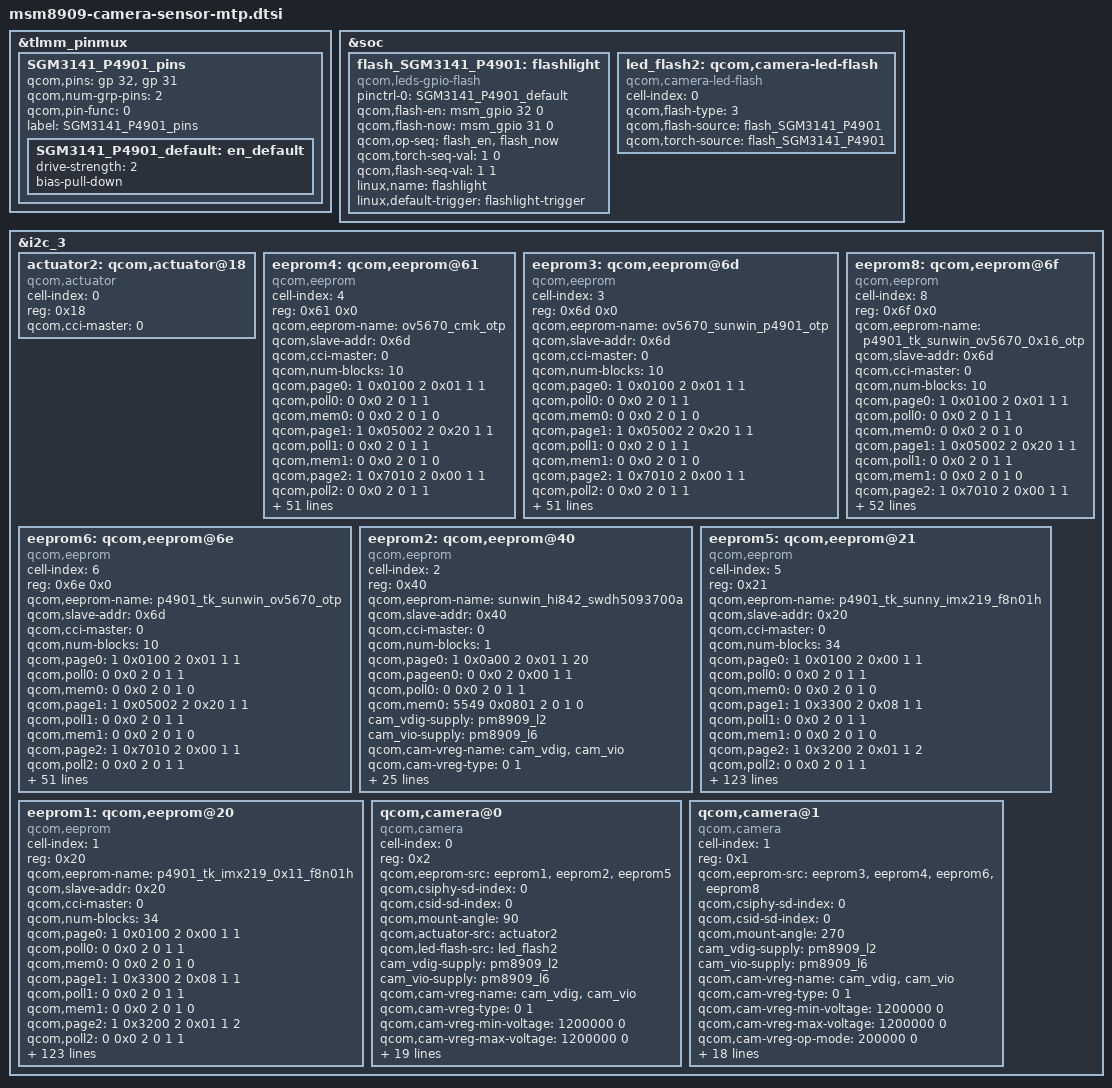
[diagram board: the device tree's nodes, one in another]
/*
 * Copyright (c) 2014-2015, The Linux Foundation. All rights reserved.
 *
 * This program is free software; you can redistribute it and/or modify
 * it under the terms of the GNU General Public License version 2 and
 * only version 2 as published by the Free Software Foundation.
 *
 * This program is distributed in the hope that it will be useful,
 * but WITHOUT ANY WARRANTY; without even the implied warranty of
 * MERCHANTABILITY or FITNESS FOR A PARTICULAR PURPOSE.  See the
 * GNU General Public License for more details.
 */

&tlmm_pinmux {
	SGM3141_P4901_pins {
		qcom,pins = <&gp 32>, <&gp 31>;
		qcom,num-grp-pins = <2>;
		qcom,pin-func = <0>;
		label = "SGM3141_P4901_pins";
		SGM3141_P4901_default: en_default {
		drive-strength = <2>;
		bias-pull-down;
		};
	};
};

&soc {
	flash_SGM3141_P4901:flashlight {
		compatible = "qcom,leds-gpio-flash";
		status = "okay";
		pinctrl-names = "flash_default";
		pinctrl-0 = <&SGM3141_P4901_default>;
		qcom,flash-en = <&msm_gpio 32 0>;
		qcom,flash-now = <&msm_gpio 31 0>;
		qcom,op-seq = "flash_en", "flash_now";
		qcom,torch-seq-val = <1 0>;
		qcom,flash-seq-val = <1 1>;
		linux,name = "flashlight";
		linux,default-trigger = "flashlight-trigger";
	};
	led_flash2: qcom,camera-led-flash {
		cell-index = <0>;
		compatible = "qcom,camera-led-flash";
		qcom,flash-type = <3>;
		qcom,flash-source = <&flash_SGM3141_P4901>;
		qcom,torch-source = <&flash_SGM3141_P4901>;
	};
};

&i2c_3 {

	actuator2: qcom,actuator@18 {
		cell-index = <0>;
		reg = <0x18>;
		compatible = "qcom,actuator";
		qcom,cci-master = <0>;
	};

      //ov5670 cmk
      eeprom4: qcom,eeprom@61{
		cell-index = <4>;
		reg = <0x61 0x0>;
		qcom,eeprom-name = "ov5670_cmk_otp";
		compatible = "qcom,eeprom";
		qcom,slave-addr = <0x6d>;
		qcom,cci-master = <0>;
		qcom,num-blocks = <10>;

		qcom,page0 = <1 0x0100 2 0x01 1 1>;
		qcom,poll0 = <0 0x0 2 0 1 1>;
		qcom,mem0 = <0 0x0 2 0 1 0>;

		qcom,page1 = <1 0x05002 2 0x20 1 1>;
		qcom,poll1 = <0 0x0 2 0 1 1>;
		qcom,mem1 = <0 0x0 2 0 1 0>;

		qcom,page2 = <1 0x7010 2 0x00 1 1>;
		qcom,poll2 = <0 0x0 2 0 1 1>;
		qcom,mem2 = <0 0x0 2 0 1 0>;

		qcom,page3 = <1 0x3d84 2 0xc0 1 1>;
		qcom,poll3 = <0 0x0 2 0 1 1>;
		qcom,mem3 = <0 0x0 2 0 1 0>;

		qcom,page4 = <1 0x3d88 2 0x70 1 1>;
		qcom,poll4 = <0 0x0 2 0 1 1>;
		qcom,mem4 = <0 0x0 2 0 1 0>;

		qcom,page5 = <1 0x3d89 2 0x10 1 1>;
		qcom,poll5 = <0 0x0 2 0 1 1>;
		qcom,mem5 = <0 0x0 2 0 1 0>;

		qcom,page6 = <1 0x3d8a 2 0x70 1 1>;
		qcom,poll6 = <0 0x0 2 0 1 1>;
		qcom,mem6 = <0 0x0 2 0 1 0>;

		qcom,page7 = <1 0x3d8b 2 0x29 1 1>;
		qcom,poll7 = <0 0x0 2 0 1 1>;
		qcom,mem7 = <0 0x0 2 0 1 0>;

		qcom,page8 = <1 0x3d81 2 0x01 1 2>;
		qcom,poll8 = <0 0x0 2 0 1 1>;
		qcom,mem8 = <26 0x7010 2 0 1 1>;

		qcom,page9 = <1 0x05002 2 0x28 1 1>;
		qcom,poll9 = <0 0x0 2 0 1 1>;
		qcom,mem9 = <0 0x0 2 0 1 0>;

		cam_vdig-supply = <&pm8909_l2>;
		cam_vio-supply = <&pm8909_l6>;
		qcom,cam-vreg-name = "cam_vdig","cam_vio";
		qcom,cam-vreg-type = <0 1>;
		qcom,cam-vreg-min-voltage = <1200000 0>;
		qcom,cam-vreg-max-voltage = <1200000 0>;
		qcom,cam-vreg-op-mode = <200000 0>;
		pinctrl-names = "cam_default", "cam_suspend";
		pinctrl-0 = <&cam_sensor_mclk1_default
				&cam_sensor_front_default>;
		pinctrl-1 = <&cam_sensor_mclk1_sleep &cam_sensor_front_sleep>;
		gpios = <&msm_gpio 27 0>,
			<&msm_gpio 28 0>,
			<&msm_gpio 33 0>,
			<&msm_gpio 112 0>;
		qcom,gpio-reset = <1>;
		qcom,gpio-standby = <2>;
		qcom,gpio-vana = <3>;
		qcom,gpio-req-tbl-num = <0 1 2 3>;
		qcom,gpio-req-tbl-flags = <1 0 0 0>;
		qcom,gpio-req-tbl-label = "CAMIF_MCLK",
					"CAM_RESET",
					"CAM_STANDBY",
					"CAM_VANA";
		qcom,cam-power-seq-type = "sensor_clk",
			"sensor_gpio",
			"sensor_gpio",
			"sensor_gpio";
		qcom,cam-power-seq-val = "sensor_cam_mclk",
			"sensor_gpio_reset",
			"sensor_gpio_standby",
			"sensor_gpio_vana";
		qcom,cam-power-seq-cfg-val = <24000000 1 1 1>;
		qcom,cam-power-seq-delay = <5 10 10 10>;

		clocks = <&clock_gcc clk_mclk1_clk_src>,
				<&clock_gcc clk_gcc_camss_mclk1_clk>;
		clock-names = "cam_src_clk", "cam_clk";
	};

      //ov5670
      eeprom3: qcom,eeprom@6d{
		cell-index = <3>;
		reg = <0x6d 0x0>;
		qcom,eeprom-name = "ov5670_sunwin_p4901_otp";
		compatible = "qcom,eeprom";
		qcom,slave-addr = <0x6d>;
		qcom,cci-master = <0>;
		qcom,num-blocks = <10>;

		qcom,page0 = <1 0x0100 2 0x01 1 1>;
		qcom,poll0 = <0 0x0 2 0 1 1>;
		qcom,mem0 = <0 0x0 2 0 1 0>;

		qcom,page1 = <1 0x05002 2 0x20 1 1>;
		qcom,poll1 = <0 0x0 2 0 1 1>;
		qcom,mem1 = <0 0x0 2 0 1 0>;

		qcom,page2 = <1 0x7010 2 0x00 1 1>;
		qcom,poll2 = <0 0x0 2 0 1 1>;
		qcom,mem2 = <0 0x0 2 0 1 0>;

		qcom,page3 = <1 0x3d84 2 0xc0 1 1>;
		qcom,poll3 = <0 0x0 2 0 1 1>;
		qcom,mem3 = <0 0x0 2 0 1 0>;

		qcom,page4 = <1 0x3d88 2 0x70 1 1>;
		qcom,poll4 = <0 0x0 2 0 1 1>;
		qcom,mem4 = <0 0x0 2 0 1 0>;

		qcom,page5 = <1 0x3d89 2 0x10 1 1>;
		qcom,poll5 = <0 0x0 2 0 1 1>;
		qcom,mem5 = <0 0x0 2 0 1 0>;

		qcom,page6 = <1 0x3d8a 2 0x70 1 1>;
		qcom,poll6 = <0 0x0 2 0 1 1>;
		qcom,mem6 = <0 0x0 2 0 1 0>;

		qcom,page7 = <1 0x3d8b 2 0x29 1 1>;
		qcom,poll7 = <0 0x0 2 0 1 1>;
		qcom,mem7 = <0 0x0 2 0 1 0>;

		qcom,page8 = <1 0x3d81 2 0x01 1 2>;
		qcom,poll8 = <0 0x0 2 0 1 1>;
		qcom,mem8 = <26 0x7010 2 0 1 1>;

		qcom,page9 = <1 0x05002 2 0x28 1 1>;
		qcom,poll9 = <0 0x0 2 0 1 1>;
		qcom,mem9 = <0 0x0 2 0 1 0>;

		cam_vdig-supply = <&pm8909_l2>;
		cam_vio-supply = <&pm8909_l6>;
		qcom,cam-vreg-name = "cam_vdig","cam_vio";
		qcom,cam-vreg-type = <0 1>;
		qcom,cam-vreg-min-voltage = <1200000 0>;
		qcom,cam-vreg-max-voltage = <1200000 0>;
		qcom,cam-vreg-op-mode = <200000 0>;
		pinctrl-names = "cam_default", "cam_suspend";
		pinctrl-0 = <&cam_sensor_mclk1_default
				&cam_sensor_front_default>;
		pinctrl-1 = <&cam_sensor_mclk1_sleep &cam_sensor_front_sleep>;
		gpios = <&msm_gpio 27 0>,
			<&msm_gpio 28 0>,
			<&msm_gpio 33 0>,
			<&msm_gpio 112 0>;
		qcom,gpio-reset = <1>;
		qcom,gpio-standby = <2>;
		qcom,gpio-vana = <3>;
		qcom,gpio-req-tbl-num = <0 1 2 3>;
		qcom,gpio-req-tbl-flags = <1 0 0 0>;
		qcom,gpio-req-tbl-label = "CAMIF_MCLK",
					"CAM_RESET",
					"CAM_STANDBY",
					"CAM_VANA";
		qcom,cam-power-seq-type = "sensor_clk",
			"sensor_gpio",
			"sensor_gpio",
			"sensor_gpio";
		qcom,cam-power-seq-val = "sensor_cam_mclk",
			"sensor_gpio_reset",
			"sensor_gpio_standby",
			"sensor_gpio_vana";
		qcom,cam-power-seq-cfg-val = <24000000 1 1 1>;
		qcom,cam-power-seq-delay = <5 10 10 10>;

		clocks = <&clock_gcc clk_mclk1_clk_src>,
				<&clock_gcc clk_gcc_camss_mclk1_clk>;
		clock-names = "cam_src_clk", "cam_clk";
	};


 //ov5670 tk 0x16
      eeprom8: qcom,eeprom@6f{
		cell-index = <8>;
		reg = <0x6f 0x0>;
		qcom,eeprom-name = "p4901_tk_sunwin_ov5670_0x16_otp";
		compatible = "qcom,eeprom";
		qcom,slave-addr = <0x6d>;
		qcom,cci-master = <0>;
		qcom,num-blocks = <10>;

		qcom,page0 = <1 0x0100 2 0x01 1 1>;
		qcom,poll0 = <0 0x0 2 0 1 1>;
		qcom,mem0 = <0 0x0 2 0 1 0>;

		qcom,page1 = <1 0x05002 2 0x20 1 1>;
		qcom,poll1 = <0 0x0 2 0 1 1>;
		qcom,mem1 = <0 0x0 2 0 1 0>;

		qcom,page2 = <1 0x7010 2 0x00 1 1>;
		qcom,poll2 = <0 0x0 2 0 1 1>;
		qcom,mem2 = <0 0x0 2 0 1 0>;

		qcom,page3 = <1 0x3d84 2 0xc0 1 1>;
		qcom,poll3 = <0 0x0 2 0 1 1>;
		qcom,mem3 = <0 0x0 2 0 1 0>;

		qcom,page4 = <1 0x3d88 2 0x70 1 1>;
		qcom,poll4 = <0 0x0 2 0 1 1>;
		qcom,mem4 = <0 0x0 2 0 1 0>;

		qcom,page5 = <1 0x3d89 2 0x10 1 1>;
		qcom,poll5 = <0 0x0 2 0 1 1>;
		qcom,mem5 = <0 0x0 2 0 1 0>;

		qcom,page6 = <1 0x3d8a 2 0x70 1 1>;
		qcom,poll6 = <0 0x0 2 0 1 1>;
		qcom,mem6 = <0 0x0 2 0 1 0>;

		qcom,page7 = <1 0x3d8b 2 0x29 1 1>;
		qcom,poll7 = <0 0x0 2 0 1 1>;
		qcom,mem7 = <0 0x0 2 0 1 0>;

		qcom,page8 = <1 0x3d81 2 0x01 1 2>;
		qcom,poll8 = <0 0x0 2 0 1 1>;
		qcom,mem8 = <26 0x7010 2 0 1 1>;

		qcom,page9 = <1 0x05002 2 0x28 1 1>;
		qcom,poll9 = <0 0x0 2 0 1 1>;
		qcom,mem9 = <0 0x0 2 0 1 0>;

		cam_vdig-supply = <&pm8909_l2>;
		cam_vio-supply = <&pm8909_l6>;
		qcom,cam-vreg-name = "cam_vdig","cam_vio";
		qcom,cam-vreg-type = <0 1>;
		qcom,cam-vreg-min-voltage = <1200000 0>;
		qcom,cam-vreg-max-voltage = <1200000 0>;
		qcom,cam-vreg-op-mode = <200000 0>;
		pinctrl-names = "cam_default", "cam_suspend";
		pinctrl-0 = <&cam_sensor_mclk1_default
				&cam_sensor_front_default>;
		pinctrl-1 = <&cam_sensor_mclk1_sleep &cam_sensor_front_sleep>;
		gpios = <&msm_gpio 27 0>,
			<&msm_gpio 28 0>,
			<&msm_gpio 33 0>,
			<&msm_gpio 112 0>;
		qcom,gpio-reset = <1>;
		qcom,gpio-standby = <2>;
		qcom,gpio-vana = <3>;
		qcom,gpio-req-tbl-num = <0 1 2 3>;
		qcom,gpio-req-tbl-flags = <1 0 0 0>;
		qcom,gpio-req-tbl-label = "CAMIF_MCLK",
					"CAM_RESET",
					"CAM_STANDBY",
					"CAM_VANA";
		qcom,cam-power-seq-type = "sensor_clk",
			"sensor_gpio",
			"sensor_gpio",
			"sensor_gpio";
		qcom,cam-power-seq-val = "sensor_cam_mclk",
			"sensor_gpio_reset",
			"sensor_gpio_standby",
			"sensor_gpio_vana";
		qcom,cam-power-seq-cfg-val = <24000000 1 1 1>;
		qcom,cam-power-seq-delay = <5 10 10 10>;

		clocks = <&clock_gcc clk_mclk1_clk_src>,
				<&clock_gcc clk_gcc_camss_mclk1_clk>;
		clock-names = "cam_src_clk", "cam_clk";
	};

 //ov5670 tk
      eeprom6: qcom,eeprom@6e{
		cell-index = <6>;
		reg = <0x6e 0x0>;
		qcom,eeprom-name = "p4901_tk_sunwin_ov5670_otp";
		compatible = "qcom,eeprom";
		qcom,slave-addr = <0x6d>;
		qcom,cci-master = <0>;
		qcom,num-blocks = <10>;

		qcom,page0 = <1 0x0100 2 0x01 1 1>;
		qcom,poll0 = <0 0x0 2 0 1 1>;
		qcom,mem0 = <0 0x0 2 0 1 0>;

		qcom,page1 = <1 0x05002 2 0x20 1 1>;
		qcom,poll1 = <0 0x0 2 0 1 1>;
		qcom,mem1 = <0 0x0 2 0 1 0>;

		qcom,page2 = <1 0x7010 2 0x00 1 1>;
		qcom,poll2 = <0 0x0 2 0 1 1>;
		qcom,mem2 = <0 0x0 2 0 1 0>;

		qcom,page3 = <1 0x3d84 2 0xc0 1 1>;
		qcom,poll3 = <0 0x0 2 0 1 1>;
		qcom,mem3 = <0 0x0 2 0 1 0>;

		qcom,page4 = <1 0x3d88 2 0x70 1 1>;
		qcom,poll4 = <0 0x0 2 0 1 1>;
		qcom,mem4 = <0 0x0 2 0 1 0>;

		qcom,page5 = <1 0x3d89 2 0x10 1 1>;
		qcom,poll5 = <0 0x0 2 0 1 1>;
		qcom,mem5 = <0 0x0 2 0 1 0>;

		qcom,page6 = <1 0x3d8a 2 0x70 1 1>;
		qcom,poll6 = <0 0x0 2 0 1 1>;
		qcom,mem6 = <0 0x0 2 0 1 0>;

		qcom,page7 = <1 0x3d8b 2 0x29 1 1>;
		qcom,poll7 = <0 0x0 2 0 1 1>;
		qcom,mem7 = <0 0x0 2 0 1 0>;

		qcom,page8 = <1 0x3d81 2 0x01 1 2>;
		qcom,poll8 = <0 0x0 2 0 1 1>;
		qcom,mem8 = <26 0x7010 2 0 1 1>;

		qcom,page9 = <1 0x05002 2 0x28 1 1>;
		qcom,poll9 = <0 0x0 2 0 1 1>;
		qcom,mem9 = <0 0x0 2 0 1 0>;

		cam_vdig-supply = <&pm8909_l2>;
		cam_vio-supply = <&pm8909_l6>;
		qcom,cam-vreg-name = "cam_vdig","cam_vio";
		qcom,cam-vreg-type = <0 1>;
		qcom,cam-vreg-min-voltage = <1200000 0>;
		qcom,cam-vreg-max-voltage = <1200000 0>;
		qcom,cam-vreg-op-mode = <200000 0>;
		pinctrl-names = "cam_default", "cam_suspend";
		pinctrl-0 = <&cam_sensor_mclk1_default
				&cam_sensor_front_default>;
		pinctrl-1 = <&cam_sensor_mclk1_sleep &cam_sensor_front_sleep>;
		gpios = <&msm_gpio 27 0>,
			<&msm_gpio 28 0>,
			<&msm_gpio 33 0>,
			<&msm_gpio 112 0>;
		qcom,gpio-reset = <1>;
		qcom,gpio-standby = <2>;
		qcom,gpio-vana = <3>;
		qcom,gpio-req-tbl-num = <0 1 2 3>;
		qcom,gpio-req-tbl-flags = <1 0 0 0>;
		qcom,gpio-req-tbl-label = "CAMIF_MCLK",
					"CAM_RESET",
					"CAM_STANDBY",
					"CAM_VANA";
		qcom,cam-power-seq-type = "sensor_clk",
			"sensor_gpio",
			"sensor_gpio",
			"sensor_gpio";
		qcom,cam-power-seq-val = "sensor_cam_mclk",
			"sensor_gpio_reset",
			"sensor_gpio_standby",
			"sensor_gpio_vana";
		qcom,cam-power-seq-cfg-val = <24000000 1 1 1>;
		qcom,cam-power-seq-delay = <5 10 10 10>;

		clocks = <&clock_gcc clk_mclk1_clk_src>,
				<&clock_gcc clk_gcc_camss_mclk1_clk>;
		clock-names = "cam_src_clk", "cam_clk";
	};

        //HI842
	eeprom2: qcom,eeprom@40 {
		cell-index = <2>;
		reg = <0x40>;
		qcom,eeprom-name = "sunwin_hi842_swdh5093700a";
		compatible = "qcom,eeprom";
		qcom,slave-addr = <0x40>;
		qcom,cci-master = <0>;
		qcom,num-blocks = <1>;

		qcom,page0 = <1 0x0a00 2 0x01 1 20>;//sensor  sleep read regs
		qcom,pageen0 = <0 0x0 2 0x00 1 1>;
		qcom,poll0 = <0 0x0 2 0 1 1>;
		qcom,mem0 = <5549 0x0801 2 0 1 0>;

		cam_vdig-supply = <&pm8909_l2>;
		cam_vio-supply = <&pm8909_l6>;
		qcom,cam-vreg-name = "cam_vdig","cam_vio";
		qcom,cam-vreg-type = <0 1>;
		qcom,cam-vreg-min-voltage = <1200000 0>;
		qcom,cam-vreg-max-voltage = <1200000 0>;
		qcom,cam-vreg-op-mode = <200000 0>;
		pinctrl-names = "cam_default", "cam_suspend";
		pinctrl-0 = <&cam_sensor_mclk0_default &cam_sensor_rear_default>;
		pinctrl-1 = <&cam_sensor_mclk0_sleep &cam_sensor_rear_sleep>;
		gpios = <&msm_gpio 26 0>,
			<&msm_gpio 35 0>,
			<&msm_gpio 34 0>,
			<&msm_gpio 112 0>;
		qcom,gpio-reset = <1>;
		qcom,gpio-standby = <2>;
		qcom,gpio-vana = <3>;
		qcom,gpio-req-tbl-num = <0 1 2 3>;
		qcom,gpio-req-tbl-flags = <1 0 0 0>;
		qcom,gpio-req-tbl-label = "CAMIF_MCLK",
			"CAM_RESET1",
			"CAM_STANDBY",
			"CAM_VANA";
		qcom,cam-power-seq-type = "sensor_clk",
			"sensor_gpio",
			"sensor_gpio",
			"sensor_gpio";
		qcom,cam-power-seq-val = "sensor_cam_mclk",
			"sensor_gpio_reset",
			"sensor_gpio_standby",
			"sensor_gpio_vana";
		qcom,cam-power-seq-cfg-val = <24000000 1 1 1>;
		qcom,cam-power-seq-delay = <5 10 10 10>;

		clocks = <&clock_gcc clk_mclk0_clk_src>,
				<&clock_gcc clk_gcc_camss_mclk0_clk>;
		clock-names = "cam_src_clk", "cam_clk";
	};

        //IMX219 TK 4901
	eeprom5: qcom,eeprom@21{
		cell-index = <5>;
		reg = <0x21>;
		qcom,eeprom-name = "p4901_tk_sunny_imx219_f8n01h";
		compatible = "qcom,eeprom";
		qcom,slave-addr = <0x20>;
		qcom,cci-master = <0>;
		qcom,num-blocks = <34>;

		qcom,page0 = <1 0x0100 2 0x00 1 1>; //SW Standby
		qcom,poll0 = <0 0x0 2 0 1 1>;
		qcom,mem0 = <0 0x0 2 0 1 0>;
/************************module info and af info********************************/
		qcom,page1 = <1 0x3300 2 0x08 1 1>; //ECC OFF
		qcom,poll1 = <0 0x0 2 0 1 1>;
		qcom,mem1 = <0 0x0 2 0 1 0>;
		qcom,page2 = <1 0x3200 2 0x01 1 2>; //Read mode on
		qcom,poll2 = <0 0x0 2 0 1 1>;
		qcom,mem2 = <0 0x0 2 0 1 0>;
		qcom,page3 = <1 0x3202 2 0x00 1 5>; //Page 0
		qcom,poll3 = <0 0x0 2 0 1 1>;
		qcom,mem3 = <64 0x3204 2 0 1 0>;

/**********************************awb info*************************************/
		qcom,page4 = <1 0x3300 2 0x08 1 1>; //ECC OFF
		qcom,poll4 = <0 0x0 2 0 1 1>;
		qcom,mem4 = <0 0x0 2 0 1 0>;
		qcom,page5 = <1 0x3200 2 0x01 1 2>; //Read mode on
		qcom,poll5 = <0 0x0 2 0 1 1>;
		qcom,mem5 = <0 0x0 2 0 1 0>;
		qcom,page6 = <1 0x3202 2 0x01 1 5>; //Page 1
		qcom,poll6 = <0 0x0 2 0 1 1>;
		qcom,mem6 = <64 0x3204 2 0 1 0>;

/******************************lsc info group 1*********************************/
		qcom,page7 = <1 0x3300 2 0x00 1 1>; //ECC ON
		qcom,poll7 = <0 0x0 2 0 1 1>;
		qcom,mem7 = <0 0x0 2 0 1 0>;
		qcom,page8 = <1 0x3200 2 0x01 1 2>; //Read mode on
		qcom,poll8 = <0 0x0 2 0 1 0>;
		qcom,mem8 = <0 0x0 2 0 1 0>;
		qcom,page9 = <1 0x3202 2 0x02 1 5>; //Page 2
		qcom,poll9 = <0 0x0 2 0 1 1>;
		qcom,mem9 = <64 0x3204 2 0 1 0>;

		qcom,page10 = <1 0x3300 2 0x00 1 1>; //ECC ON
		qcom,poll10 = <0 0x0 2 0 1 1>;
		qcom,mem10 = <0 0x0 2 0 1 0>;
		qcom,page11 = <1 0x3200 2 0x01 1 2>; //Read mode on
		qcom,poll11 = <0 0x0 2 0 1 0>;
		qcom,mem11 = <0 0x0 2 0 1 0>;
		qcom,page12 = <1 0x3202 2 0x03 1 5>; //Page 3
		qcom,poll12 = <0 0x0 2 0 1 1>;
		qcom,mem12 = <64 0x3204 2 0 1 0>;

		qcom,page13 = <1 0x3300 2 0x00 1 1>; //ECC ON
		qcom,poll13 = <0 0x0 2 0 1 1>;
		qcom,mem13 = <0 0x0 2 0 1 0>;
		qcom,page14 = <1 0x3200 2 0x01 1 2>; //Read mode on
		qcom,poll14 = <0 0x0 2 0 1 0>;
		qcom,mem14 = <0 0x0 2 0 1 0>;
		qcom,page15 = <1 0x3202 2 0x04 1 5>; //Page 4
		qcom,poll15 = <0 0x0 2 0 1 1>;
		qcom,mem15 = <64 0x3204 2 0 1 0>; //0x3204~0x3232 47byte

		qcom,page16 = <1 0x3300 2 0x00 1 1>; //ECC ON
		qcom,poll16 = <0 0x0 2 0 1 1>;
		qcom,mem16 = <0 0x0 2 0 1 0>;
		qcom,page17 = <1 0x3200 2 0x01 1 2>; //Read mode on
		qcom,poll17 = <0 0x0 2 0 1 0>;
		qcom,mem17 = <0 0x0 2 0 1 0>;
		qcom,page18 = <1 0x3202 2 0x05 1 5>; //Page 5
		qcom,poll18 = <0 0x0 2 0 1 1>;
		qcom,mem18 = <64 0x3204 2 0 1 0>;

		qcom,page19 = <1 0x3300 2 0x00 1 1>; //ECC ON
		qcom,poll19 = <0 0x0 2 0 1 1>;
		qcom,mem19 = <0 0x0 2 0 1 0>;
		qcom,page20 = <1 0x3200 2 0x01 1 2>; //Read mode on
		qcom,poll20 = <0 0x0 2 0 1 0>;
		qcom,mem20 = <0 0x0 2 0 1 0>;
		qcom,page21 = <1 0x3202 2 0x06 1 5>; //Page 6
		qcom,poll21 = <0 0x0 2 0 1 1>;
		qcom,mem21 = <64 0x3204 2 0 1 0>; //0x3204~0x3232 47byte

/******************************lsc info group 2*********************************/
		qcom,page22 = <1 0x3300 2 0x00 1 1>; //ECC ON
		qcom,poll22 = <0 0x0 2 0 1 1>;
		qcom,mem22 = <0 0x0 2 0 1 0>;
		qcom,page23 = <1 0x3200 2 0x01 1 2>; //Read mode on
		qcom,poll23 = <0 0x0 2 0 1 0>;
		qcom,mem23 = <0 0x0 2 0 1 0>;
		qcom,page24 = <1 0x3202 2 0x07 1 5>; //Page 7
		qcom,poll24 = <0 0x0 2 0 1 1>;
		qcom,mem24 = <64 0x3204 2 0 1 0>; //0x3222~0x3243 34byte

		qcom,page25 = <1 0x3300 2 0x00 1 1>; //ECC ON
		qcom,poll25 = <0 0x0 2 0 1 1>;
		qcom,mem25 = <0 0x0 2 0 1 0>;
		qcom,page26 = <1 0x3200 2 0x01 1 2>; //Read mode on
		qcom,poll26 = <0 0x0 2 0 1 0>;
		qcom,mem26 = <0 0x0 2 0 1 0>;
		qcom,page27 = <1 0x3202 2 0x08 1 5>; //Page 8
		qcom,poll27 = <0 0x0 2 0 1 1>;
		qcom,mem27 = <64 0x3204 2 0 1 0>;

		qcom,page28 = <1 0x3300 2 0x00 1 1>; //ECC ON
		qcom,poll28 = <0 0x0 2 0 1 1>;
		qcom,mem28 = <0 0x0 2 0 1 0>;
		qcom,page29 = <1 0x3200 2 0x01 1 2>; //Read mode on
		qcom,poll29 = <0 0x0 2 0 1 0>;
		qcom,mem29 = <0 0x0 2 0 1 0>;
		qcom,page30 = <1 0x3202 2 0x09 1 5>; //Page 9
		qcom,poll30 = <0 0x0 2 0 1 1>;
		qcom,mem30 = <64 0x3204 2 0 1 0>;

		qcom,page31 = <1 0x3300 2 0x00 1 1>; //ECC ON
		qcom,poll31 = <0 0x0 2 0 1 1>;
		qcom,mem31 = <0 0x0 2 0 1 0>;
		qcom,page32 = <1 0x3200 2 0x01 1 2>; //Read mode on
		qcom,poll32 = <0 0x0 2 0 1 0>;
		qcom,mem32 = <0 0x0 2 0 1 0>;
		qcom,page33 = <1 0x3202 2 0x0a 1 5>; //Page 10
		qcom,poll33 = <0 0x0 2 0 1 1>;
		qcom,mem33 = <64 0x3204 2 0 1 0>; //0x3204~0x3210 13byte

		cam_vdig-supply = <&pm8909_l2>;
		cam_vio-supply = <&pm8909_l6>;
		qcom,cam-vreg-name = "cam_vdig", "cam_vio";
		qcom,cam-vreg-type = <0 1>;
		qcom,cam-vreg-min-voltage = <1200000 0>;
		qcom,cam-vreg-max-voltage = <1200000 0>;
		qcom,cam-vreg-op-mode = <200000 0>;
		pinctrl-names = "cam_default", "cam_suspend";
		pinctrl-0 = <&cam_sensor_mclk0_default &cam_sensor_rear_default>;
		pinctrl-1 = <&cam_sensor_mclk0_sleep &cam_sensor_rear_sleep>;
		gpios = <&msm_gpio 26 0>,
			<&msm_gpio 35 0>,
			<&msm_gpio 34 0>,
			<&msm_gpio 112 0>;
		qcom,gpio-reset = <1>;
		qcom,gpio-standby = <2>;
		qcom,gpio-vana = <3>;
		qcom,gpio-req-tbl-num = <0 1 2 3>;
		qcom,gpio-req-tbl-flags = <1 0 0 0>;
		qcom,gpio-req-tbl-label = "CAMIF_MCLK",
			"CAM_RESET1",
			"CAM_STANDBY",
			"CAM_VANA";
		qcom,cam-power-seq-type = "sensor_clk",
			"sensor_gpio",
			"sensor_gpio",
			"sensor_gpio";
		qcom,cam-power-seq-val = "sensor_cam_mclk",
			"sensor_gpio_reset",
			"sensor_gpio_standby",
			"sensor_gpio_vana";
		qcom,cam-power-seq-cfg-val = <24000000 1 1 1>;
		qcom,cam-power-seq-delay = <5 5 5 5>;

		clocks = <&clock_gcc clk_mclk0_clk_src>,
				<&clock_gcc clk_gcc_camss_mclk0_clk>;
		clock-names = "cam_src_clk", "cam_clk";
	};
//IMX219 0x11 TK 4901
	eeprom1: qcom,eeprom@20{
		cell-index = <1>;
		reg = <0x20>;
		qcom,eeprom-name = "p4901_tk_imx219_0x11_f8n01h";
		compatible = "qcom,eeprom";
		qcom,slave-addr = <0x20>;
		qcom,cci-master = <0>;
		qcom,num-blocks = <34>;

		qcom,page0 = <1 0x0100 2 0x00 1 1>; //SW Standby
		qcom,poll0 = <0 0x0 2 0 1 1>;
		qcom,mem0 = <0 0x0 2 0 1 0>;
/************************module info and af info********************************/
		qcom,page1 = <1 0x3300 2 0x08 1 1>; //ECC OFF
		qcom,poll1 = <0 0x0 2 0 1 1>;
		qcom,mem1 = <0 0x0 2 0 1 0>;
		qcom,page2 = <1 0x3200 2 0x01 1 2>; //Read mode on
		qcom,poll2 = <0 0x0 2 0 1 1>;
		qcom,mem2 = <0 0x0 2 0 1 0>;
		qcom,page3 = <1 0x3202 2 0x00 1 5>; //Page 0
		qcom,poll3 = <0 0x0 2 0 1 1>;
		qcom,mem3 = <64 0x3204 2 0 1 0>;

/**********************************awb info*************************************/
		qcom,page4 = <1 0x3300 2 0x08 1 1>; //ECC OFF
		qcom,poll4 = <0 0x0 2 0 1 1>;
		qcom,mem4 = <0 0x0 2 0 1 0>;
		qcom,page5 = <1 0x3200 2 0x01 1 2>; //Read mode on
		qcom,poll5 = <0 0x0 2 0 1 1>;
		qcom,mem5 = <0 0x0 2 0 1 0>;
		qcom,page6 = <1 0x3202 2 0x01 1 5>; //Page 1
		qcom,poll6 = <0 0x0 2 0 1 1>;
		qcom,mem6 = <64 0x3204 2 0 1 0>;

/******************************lsc info group 1*********************************/
		qcom,page7 = <1 0x3300 2 0x00 1 1>; //ECC ON
		qcom,poll7 = <0 0x0 2 0 1 1>;
		qcom,mem7 = <0 0x0 2 0 1 0>;
		qcom,page8 = <1 0x3200 2 0x01 1 2>; //Read mode on
		qcom,poll8 = <0 0x0 2 0 1 0>;
		qcom,mem8 = <0 0x0 2 0 1 0>;
		qcom,page9 = <1 0x3202 2 0x02 1 5>; //Page 2
		qcom,poll9 = <0 0x0 2 0 1 1>;
		qcom,mem9 = <64 0x3204 2 0 1 0>;

		qcom,page10 = <1 0x3300 2 0x00 1 1>; //ECC ON
		qcom,poll10 = <0 0x0 2 0 1 1>;
		qcom,mem10 = <0 0x0 2 0 1 0>;
		qcom,page11 = <1 0x3200 2 0x01 1 2>; //Read mode on
		qcom,poll11 = <0 0x0 2 0 1 0>;
		qcom,mem11 = <0 0x0 2 0 1 0>;
		qcom,page12 = <1 0x3202 2 0x03 1 5>; //Page 3
		qcom,poll12 = <0 0x0 2 0 1 1>;
		qcom,mem12 = <64 0x3204 2 0 1 0>;

		qcom,page13 = <1 0x3300 2 0x00 1 1>; //ECC ON
		qcom,poll13 = <0 0x0 2 0 1 1>;
		qcom,mem13 = <0 0x0 2 0 1 0>;
		qcom,page14 = <1 0x3200 2 0x01 1 2>; //Read mode on
		qcom,poll14 = <0 0x0 2 0 1 0>;
		qcom,mem14 = <0 0x0 2 0 1 0>;
		qcom,page15 = <1 0x3202 2 0x04 1 5>; //Page 4
		qcom,poll15 = <0 0x0 2 0 1 1>;
		qcom,mem15 = <64 0x3204 2 0 1 0>; //0x3204~0x3232 47byte

		qcom,page16 = <1 0x3300 2 0x00 1 1>; //ECC ON
		qcom,poll16 = <0 0x0 2 0 1 1>;
		qcom,mem16 = <0 0x0 2 0 1 0>;
		qcom,page17 = <1 0x3200 2 0x01 1 2>; //Read mode on
		qcom,poll17 = <0 0x0 2 0 1 0>;
		qcom,mem17 = <0 0x0 2 0 1 0>;
		qcom,page18 = <1 0x3202 2 0x05 1 5>; //Page 5
		qcom,poll18 = <0 0x0 2 0 1 1>;
		qcom,mem18 = <64 0x3204 2 0 1 0>;

		qcom,page19 = <1 0x3300 2 0x00 1 1>; //ECC ON
		qcom,poll19 = <0 0x0 2 0 1 1>;
		qcom,mem19 = <0 0x0 2 0 1 0>;
		qcom,page20 = <1 0x3200 2 0x01 1 2>; //Read mode on
		qcom,poll20 = <0 0x0 2 0 1 0>;
		qcom,mem20 = <0 0x0 2 0 1 0>;
		qcom,page21 = <1 0x3202 2 0x06 1 5>; //Page 6
		qcom,poll21 = <0 0x0 2 0 1 1>;
		qcom,mem21 = <64 0x3204 2 0 1 0>; //0x3204~0x3232 47byte

/******************************lsc info group 2*********************************/
		qcom,page22 = <1 0x3300 2 0x00 1 1>; //ECC ON
		qcom,poll22 = <0 0x0 2 0 1 1>;
		qcom,mem22 = <0 0x0 2 0 1 0>;
		qcom,page23 = <1 0x3200 2 0x01 1 2>; //Read mode on
		qcom,poll23 = <0 0x0 2 0 1 0>;
		qcom,mem23 = <0 0x0 2 0 1 0>;
		qcom,page24 = <1 0x3202 2 0x07 1 5>; //Page 7
		qcom,poll24 = <0 0x0 2 0 1 1>;
		qcom,mem24 = <64 0x3204 2 0 1 0>; //0x3222~0x3243 34byte

		qcom,page25 = <1 0x3300 2 0x00 1 1>; //ECC ON
		qcom,poll25 = <0 0x0 2 0 1 1>;
		qcom,mem25 = <0 0x0 2 0 1 0>;
		qcom,page26 = <1 0x3200 2 0x01 1 2>; //Read mode on
		qcom,poll26 = <0 0x0 2 0 1 0>;
		qcom,mem26 = <0 0x0 2 0 1 0>;
		qcom,page27 = <1 0x3202 2 0x08 1 5>; //Page 8
		qcom,poll27 = <0 0x0 2 0 1 1>;
		qcom,mem27 = <64 0x3204 2 0 1 0>;

		qcom,page28 = <1 0x3300 2 0x00 1 1>; //ECC ON
		qcom,poll28 = <0 0x0 2 0 1 1>;
		qcom,mem28 = <0 0x0 2 0 1 0>;
		qcom,page29 = <1 0x3200 2 0x01 1 2>; //Read mode on
		qcom,poll29 = <0 0x0 2 0 1 0>;
		qcom,mem29 = <0 0x0 2 0 1 0>;
		qcom,page30 = <1 0x3202 2 0x09 1 5>; //Page 9
		qcom,poll30 = <0 0x0 2 0 1 1>;
		qcom,mem30 = <64 0x3204 2 0 1 0>;

		qcom,page31 = <1 0x3300 2 0x00 1 1>; //ECC ON
		qcom,poll31 = <0 0x0 2 0 1 1>;
		qcom,mem31 = <0 0x0 2 0 1 0>;
		qcom,page32 = <1 0x3200 2 0x01 1 2>; //Read mode on
		qcom,poll32 = <0 0x0 2 0 1 0>;
		qcom,mem32 = <0 0x0 2 0 1 0>;
		qcom,page33 = <1 0x3202 2 0x0a 1 5>; //Page 10
		qcom,poll33 = <0 0x0 2 0 1 1>;
		qcom,mem33 = <64 0x3204 2 0 1 0>; //0x3204~0x3210 13byte

		cam_vdig-supply = <&pm8909_l2>;
		cam_vio-supply = <&pm8909_l6>;
		qcom,cam-vreg-name = "cam_vdig", "cam_vio";
		qcom,cam-vreg-type = <0 1>;
		qcom,cam-vreg-min-voltage = <1200000 0>;
		qcom,cam-vreg-max-voltage = <1200000 0>;
		qcom,cam-vreg-op-mode = <200000 0>;
		pinctrl-names = "cam_default", "cam_suspend";
		pinctrl-0 = <&cam_sensor_mclk0_default &cam_sensor_rear_default>;
		pinctrl-1 = <&cam_sensor_mclk0_sleep &cam_sensor_rear_sleep>;
		gpios = <&msm_gpio 26 0>,
			<&msm_gpio 35 0>,
			<&msm_gpio 34 0>,
			<&msm_gpio 112 0>;
		qcom,gpio-reset = <1>;
		qcom,gpio-standby = <2>;
		qcom,gpio-vana = <3>;
		qcom,gpio-req-tbl-num = <0 1 2 3>;
		qcom,gpio-req-tbl-flags = <1 0 0 0>;
		qcom,gpio-req-tbl-label = "CAMIF_MCLK",
			"CAM_RESET1",
			"CAM_STANDBY",
			"CAM_VANA";
		qcom,cam-power-seq-type = "sensor_clk",
			"sensor_gpio",
			"sensor_gpio",
			"sensor_gpio";
		qcom,cam-power-seq-val = "sensor_cam_mclk",
			"sensor_gpio_reset",
			"sensor_gpio_standby",
			"sensor_gpio_vana";
		qcom,cam-power-seq-cfg-val = <24000000 1 1 1>;
		qcom,cam-power-seq-delay = <5 5 5 5>;

		clocks = <&clock_gcc clk_mclk0_clk_src>,
				<&clock_gcc clk_gcc_camss_mclk0_clk>;
		clock-names = "cam_src_clk", "cam_clk";
	};


	qcom,camera@0 {
		cell-index = <0>;
		compatible = "qcom,camera";
		reg = <0x2>;
		qcom,eeprom-src = <&eeprom1 &eeprom2 &eeprom5>;
		qcom,csiphy-sd-index = <0>;
		qcom,csid-sd-index = <0>;
		qcom,mount-angle = <90>;
		qcom,actuator-src = <&actuator2>;
		qcom,led-flash-src = <&led_flash2>;
		cam_vdig-supply = <&pm8909_l2>;
		cam_vio-supply = <&pm8909_l6>;
		qcom,cam-vreg-name = "cam_vdig", "cam_vio";
		qcom,cam-vreg-type = <0 1>;
		qcom,cam-vreg-min-voltage = <1200000 0>;
		qcom,cam-vreg-max-voltage = <1200000 0>;
		qcom,cam-vreg-op-mode = <200000 0>;
		pinctrl-names = "cam_default", "cam_suspend";
		pinctrl-0 = <&cam_sensor_mclk0_default &cam_sensor_rear_default>;
		pinctrl-1 = <&cam_sensor_mclk0_sleep &cam_sensor_rear_sleep>;
		gpios = <&msm_gpio 26 0>,
			<&msm_gpio 35 0>,
			<&msm_gpio 34 0>,
			<&msm_gpio 112 0>;
		qcom,gpio-reset = <1>;
		qcom,gpio-standby = <2>;
		qcom,gpio-vana = <3>;
		qcom,gpio-req-tbl-num = <0 1 2 3>;
		qcom,gpio-req-tbl-flags = <1 0 0 0>;
		qcom,gpio-req-tbl-label = "CAMIF_MCLK",
			"CAM_RESET1",
			"CAM_STANDBY",
			"CAM_VANA";
		qcom,sensor-position = <0>;
		qcom,sensor-mode = <0>;
		qcom,cci-master = <0>;
		status = "ok";
		clocks = <&clock_gcc clk_mclk0_clk_src>,
				<&clock_gcc clk_gcc_camss_mclk0_clk>;
		clock-names = "cam_src_clk", "cam_clk";
	};

	qcom,camera@1 {
		cell-index = <1>;
		compatible = "qcom,camera";
		reg = <0x1>;
		qcom,eeprom-src = <&eeprom3 &eeprom4 &eeprom6 &eeprom8>;
		qcom,csiphy-sd-index = <0>;
		qcom,csid-sd-index = <0>;
		qcom,mount-angle = <270>;
		cam_vdig-supply = <&pm8909_l2>;
		cam_vio-supply = <&pm8909_l6>;
		qcom,cam-vreg-name = "cam_vdig","cam_vio";
		qcom,cam-vreg-type = <0 1>;
		qcom,cam-vreg-min-voltage = <1200000 0>;
		qcom,cam-vreg-max-voltage = <1200000 0>;
		qcom,cam-vreg-op-mode = <200000 0>;
		pinctrl-names = "cam_default", "cam_suspend";
		pinctrl-0 = <&cam_sensor_mclk1_default
				&cam_sensor_front_default>;
		pinctrl-1 = <&cam_sensor_mclk1_sleep &cam_sensor_front_sleep>;
		gpios = <&msm_gpio 27 0>,
			<&msm_gpio 28 0>,
			<&msm_gpio 33 0>,
			<&msm_gpio 112 0>;
		qcom,gpio-reset = <1>;
		qcom,gpio-standby = <2>;
		qcom,gpio-vana = <3>;
		qcom,gpio-req-tbl-num = <0 1 2 3>;
		qcom,gpio-req-tbl-flags = <1 0 0 0>;
		qcom,gpio-req-tbl-label = "CAMIF_MCLK",
					"CAM_RESET",
					"CAM_STANDBY",
					"CAM_VANA";
		qcom,sensor-position = <1>;
		qcom,sensor-mode = <0>;
		qcom,cci-master = <0>;
		status = "ok";
		clocks = <&clock_gcc clk_mclk1_clk_src>,
				<&clock_gcc clk_gcc_camss_mclk1_clk>;
		clock-names = "cam_src_clk", "cam_clk";
	};
};
